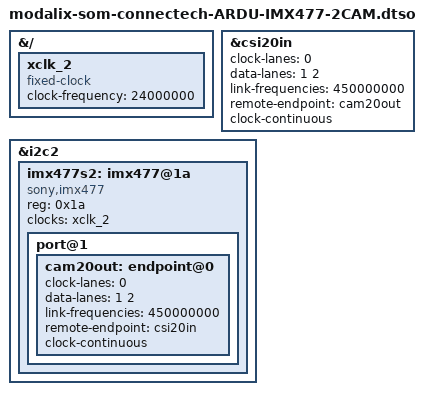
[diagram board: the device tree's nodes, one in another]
// SPDX-License-Identifier: (GPL-2.0+ OR MIT)
/*
 * Copyright (c) 2026 SiMa ai
 */

/dts-v1/;
/plugin/;

#include "modalix-som-connectech-2CAM.dtsi"

&{/} {
        xclk_2: xclk_2 {
                status = "okay";
                compatible = "fixed-clock";
                #clock-cells = <0>;
                clock-frequency = <24000000>;
        };
};

&csi20in {
    clock-lanes = <0>;
    data-lanes = <1 2>;
    link-frequencies = /bits/ 64 <450000000>;
    remote-endpoint = <&cam20out>;
    clock-continuous;
};

&i2c2 {
        imx477s2: imx477@1a {
                compatible = "sony,imx477";
                reg = <0x1a>;

                clocks = <&xclk_2>;
                clock-names = "xclk";

                port@1 {
                        cam20out: endpoint@0 {
                                clock-lanes = <0>;
                                data-lanes = <1 2>;
                                link-frequencies = /bits/ 64 <450000000>;
                                remote-endpoint = <&csi20in>;
                                clock-continuous;
                        };
                };
        };
};
